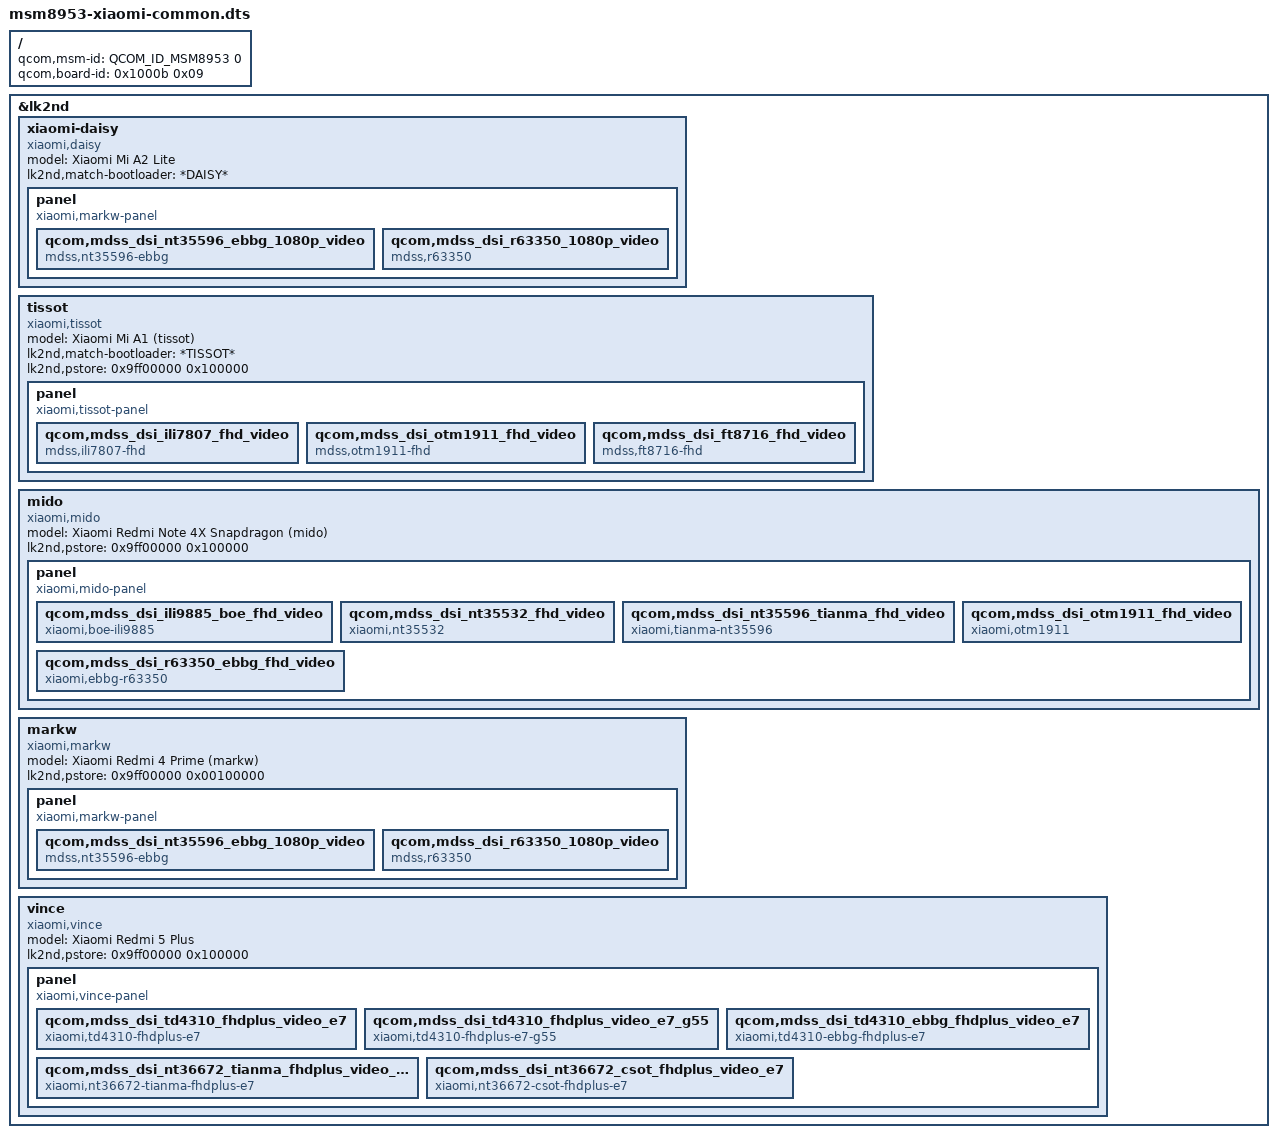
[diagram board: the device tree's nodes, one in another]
// SPDX-License-Identifier: BSD-3-Clause
#include <skeleton64.dtsi>
#include <lk2nd.dtsi>

/ {
	qcom,msm-id = <QCOM_ID_MSM8953 0>;
	qcom,board-id= <0x1000b 0x09>;
};

&lk2nd {
	xiaomi-daisy {
		model = "Xiaomi Mi A2 Lite";
		compatible = "xiaomi,daisy";
		lk2nd,match-bootloader = "*DAISY*";

		panel {
			compatible = "xiaomi,markw-panel";

			qcom,mdss_dsi_nt35596_ebbg_1080p_video {
				compatible = "mdss,nt35596-ebbg";
			};
			qcom,mdss_dsi_r63350_1080p_video {
				compatible = "mdss,r63350";
			};
		};
	};

	tissot {
		model = "Xiaomi Mi A1 (tissot)";
		compatible = "xiaomi,tissot";
		lk2nd,match-bootloader = "*TISSOT*";
		lk2nd,pstore = <0x9ff00000 0x100000>;

		panel {
			compatible = "xiaomi,tissot-panel";

			qcom,mdss_dsi_ili7807_fhd_video {
				compatible = "mdss,ili7807-fhd";
			};
			qcom,mdss_dsi_otm1911_fhd_video {
				compatible = "mdss,otm1911-fhd";
			};
			qcom,mdss_dsi_ft8716_fhd_video {
				compatible = "mdss,ft8716-fhd";
			};
		};
	};

	mido {
		model = "Xiaomi Redmi Note 4X Snapdragon (mido)";
		compatible = "xiaomi,mido";
		lk2nd,pstore = <0x9ff00000 0x100000>;

		panel {
			compatible = "xiaomi,mido-panel";

			qcom,mdss_dsi_ili9885_boe_fhd_video {
				compatible = "xiaomi,boe-ili9885";
			};

			qcom,mdss_dsi_nt35532_fhd_video {
				compatible = "xiaomi,nt35532";
			};

			qcom,mdss_dsi_nt35596_tianma_fhd_video {
				compatible = "xiaomi,tianma-nt35596";
			};

			qcom,mdss_dsi_otm1911_fhd_video {
				compatible = "xiaomi,otm1911";
			};

			qcom,mdss_dsi_r63350_ebbg_fhd_video {
				compatible = "xiaomi,ebbg-r63350";
			};
		};
	};

	markw {
		model = "Xiaomi Redmi 4 Prime (markw)";
		compatible = "xiaomi,markw", "qcom,msm8953", "lk2nd,device";
		lk2nd,pstore = <0x9ff00000 0x00100000>;

		panel {
			compatible = "xiaomi,markw-panel";

			qcom,mdss_dsi_nt35596_ebbg_1080p_video {
				compatible = "mdss,nt35596-ebbg";
			};
			qcom,mdss_dsi_r63350_1080p_video {
				compatible = "mdss,r63350";
			};
		};
	};

	vince {
		model = "Xiaomi Redmi 5 Plus";
		compatible = "xiaomi,vince";
		lk2nd,pstore = <0x9ff00000 0x100000>;

		panel {
			compatible = "xiaomi,vince-panel";
			qcom,mdss_dsi_td4310_fhdplus_video_e7 {
				compatible = "xiaomi,td4310-fhdplus-e7";
			};
			qcom,mdss_dsi_td4310_fhdplus_video_e7_g55 {
				compatible = "xiaomi,td4310-fhdplus-e7-g55";
			};
			qcom,mdss_dsi_td4310_ebbg_fhdplus_video_e7 {
				compatible = "xiaomi,td4310-ebbg-fhdplus-e7";
			};
			qcom,mdss_dsi_nt36672_tianma_fhdplus_video_e7 {
				compatible = "xiaomi,nt36672-tianma-fhdplus-e7";
			};
			qcom,mdss_dsi_nt36672_csot_fhdplus_video_e7 {
				compatible = "xiaomi,nt36672-csot-fhdplus-e7";
			};
		};
	};
};
